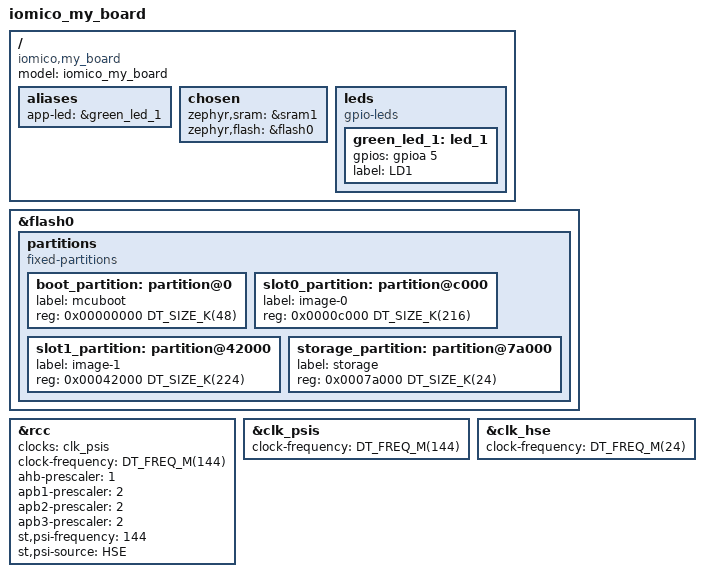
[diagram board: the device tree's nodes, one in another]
/dts-v1/;
#include <st/c5/stm32c562Xe.dtsi>


/ {
	model = "iomico_my_board";
	compatible = "iomico,my_board";

	aliases {
		app-led = &green_led_1;
	};

	chosen {
		zephyr,sram = &sram1;
		zephyr,flash = &flash0;
	};

	leds{
		compatible = "gpio-leds";

		green_led_1: led_1 {
			/* LD1 may conflict with SPI1 SCK on PA5 */
			gpios = <&gpioa 5 GPIO_ACTIVE_HIGH>;
			label = "LD1";
		};
	};
};

&flash0 {
	partitions {
		compatible = "fixed-partitions";
		#address-cells = <1>;
		#size-cells = <1>;

		boot_partition: partition@0 {
			label = "mcuboot";
			reg = <0x00000000 DT_SIZE_K(48)>;
		};

		slot0_partition: partition@c000 {
			label = "image-0";
			reg = <0x0000c000 DT_SIZE_K(216)>;
		};

		slot1_partition: partition@42000 {
			label = "image-1";
			reg = <0x00042000 DT_SIZE_K(224)>;
		};

		storage_partition: partition@7a000 {
			label = "storage";
			reg = <0x0007a000 DT_SIZE_K(24)>;
		};
	};
};

&rcc {
	clocks = <&clk_psis>;
	clock-frequency = <DT_FREQ_M(144)>;
	ahb-prescaler = <1>;
	apb1-prescaler = <2>;
	apb2-prescaler = <2>;
	apb3-prescaler = <2>;
	st,psi-frequency = <144>;
	st,psi-source = "HSE";
};

&clk_psis {
	clock-frequency = <DT_FREQ_M(144)>;
	status = "okay";
};

&clk_hse {
	clock-frequency = <DT_FREQ_M(24)>;
	status = "okay";
};
